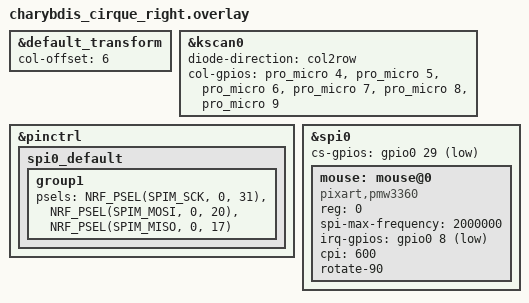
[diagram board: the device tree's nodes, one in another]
#include "charybdis_cirque.dtsi"

&default_transform {
    col-offset = <6>;
};

&kscan0 {
    diode-direction = "col2row";
    col-gpios
        = <&pro_micro 4 (GPIO_ACTIVE_HIGH)> // COL0
        , <&pro_micro 5 (GPIO_ACTIVE_HIGH)> // COL1
        , <&pro_micro 6 (GPIO_ACTIVE_HIGH)> // COL2
        , <&pro_micro 7 (GPIO_ACTIVE_HIGH)> // COL3
        , <&pro_micro 8 (GPIO_ACTIVE_HIGH)> // COL1
        , <&pro_micro 9 (GPIO_ACTIVE_HIGH)> // COL2
    ;
};


&pinctrl {
    spi0_default: spi0_default {
        group1 {
            psels = <NRF_PSEL(SPIM_SCK, 0, 31)>,
                    <NRF_PSEL(SPIM_MOSI, 0, 20)>,
                    <NRF_PSEL(SPIM_MISO, 0, 17)>;
        };
    };
};

&spi0 {
    status = "okay";
    cs-gpios = <&gpio0 29 GPIO_ACTIVE_LOW>;
    mouse: mouse@0 {
        compatible = "pixart,pmw3360";
        status = "okay";
        reg = <0>;
        spi-max-frequency = <2000000>;

        /* pmw3360 driver parameters */
        irq-gpios = <&gpio0 8 (GPIO_ACTIVE_LOW | GPIO_PULL_UP)>;
        cpi = <600>;
        rotate-90;
    };
};
/* &spi0 { */
/*   status = "okay"; */
/* }; */
/**/
/* &mouse { */
/*   status = "okay"; */
/* }; */

/* &nice_nano_spi { */
/*     status = "okay"; */
/* }; */
/**/
/* &trackball { */
/*     status = "okay"; */
/* }; */
